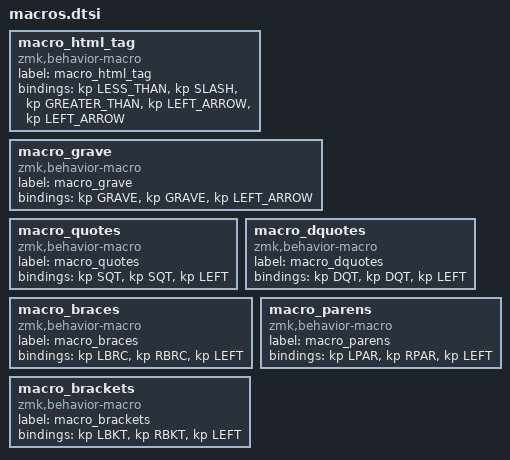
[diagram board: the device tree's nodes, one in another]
macro_html_tag: macro_html_tag{
compatible = "zmk,behavior-macro";
label = "macro_html_tag";
#binding-cells = <0>;
bindings = <&kp LESS_THAN>, <&kp SLASH>, <&kp GREATER_THAN>, <&kp LEFT_ARROW>, <&kp LEFT_ARROW>;
};
macro_grave: macro_grave{
compatible = "zmk,behavior-macro";
label = "macro_grave";
#binding-cells = <0>;
bindings = <&kp GRAVE>, <&kp GRAVE>, <&kp LEFT_ARROW>;
};
macro_quotes: macro_quotes{
compatible = "zmk,behavior-macro";
label = "macro_quotes";
#binding-cells = <0>;
bindings = <&kp SQT>, <&kp SQT>, <&kp LEFT>;
};
macro_dquotes: macro_dquotes{
compatible = "zmk,behavior-macro";
label = "macro_dquotes";
#binding-cells = <0>;
bindings = <&kp DQT>, <&kp DQT>, <&kp LEFT>;
};
macro_braces: macro_braces{
compatible = "zmk,behavior-macro";
label = "macro_braces";
#binding-cells = <0>;
bindings = <&kp LBRC>, <&kp RBRC>, <&kp LEFT>;
};
macro_parens: macro_parens{
compatible = "zmk,behavior-macro";
label = "macro_parens";
#binding-cells = <0>;
bindings = <&kp LPAR>, <&kp RPAR>, <&kp LEFT>;
};
macro_brackets: macro_brackets{
compatible = "zmk,behavior-macro";
label = "macro_brackets";
#binding-cells = <0>;
bindings = <&kp LBKT>, <&kp RBKT>, <&kp LEFT>;
};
